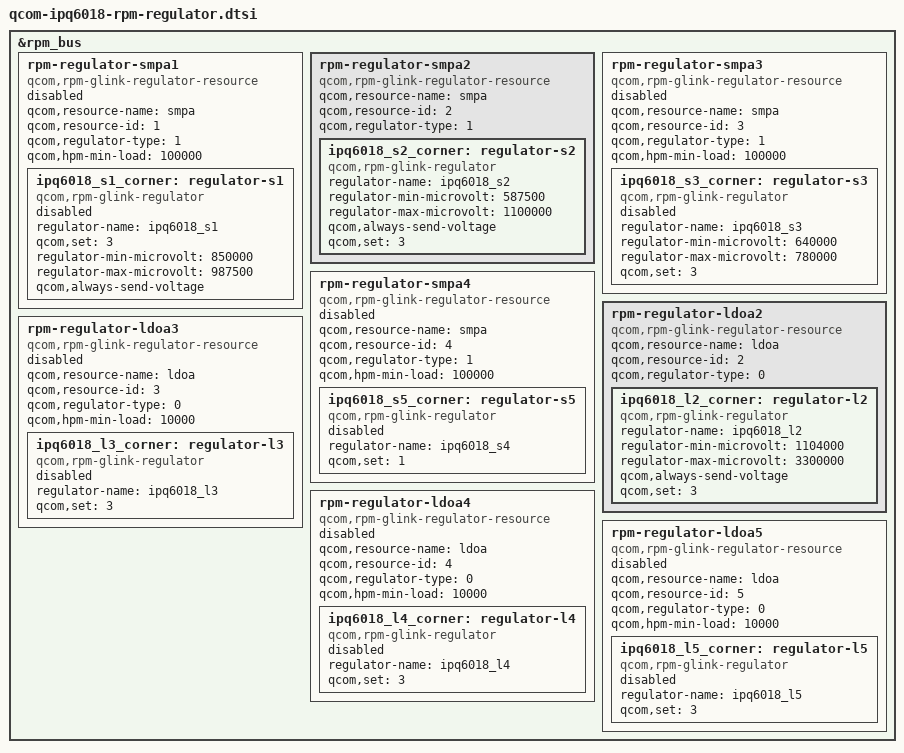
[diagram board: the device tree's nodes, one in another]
/*
 * Copyright (c) 2019, The Linux Foundation. All rights reserved.
 *
 * Permission to use, copy, modify, and/or distribute this software for any
 * purpose with or without fee is hereby granted, provided that the above
 * copyright notice and this permission notice appear in all copies.
 *
 * THE SOFTWARE IS PROVIDED "AS IS" AND THE AUTHOR DISCLAIMS ALL WARRANTIES
 * WITH REGARD TO THIS SOFTWARE INCLUDING ALL IMPLIED WARRANTIES OF
 * MERCHANTABILITY AND FITNESS. IN NO EVENT SHALL THE AUTHOR BE LIABLE FOR
 * ANY SPECIAL, DIRECT, INDIRECT, OR CONSEQUENTIAL DAMAGES OR ANY DAMAGES
 * WHATSOEVER RESULTING FROM LOSS OF USE, DATA OR PROFITS, WHETHER IN AN
 * ACTION OF CONTRACT, NEGLIGENCE OR OTHER TORTIOUS ACTION, ARISING OUT OF
 * OR IN CONNECTION WITH THE USE OR PERFORMANCE OF THIS SOFTWARE.
 */

&rpm_bus {
	rpm-regulator-smpa1 {
		compatible = "qcom,rpm-glink-regulator-resource";
		qcom,resource-name = "smpa";
		qcom,resource-id = <1>;
		qcom,regulator-type = <1>;
		qcom,hpm-min-load = <100000>;
		status = "disabled";

		ipq6018_s1_corner: regulator-s1 {
			compatible = "qcom,rpm-glink-regulator";
			regulator-name = "ipq6018_s1";
			qcom,set = <3>;
			regulator-min-microvolt = <850000>;
			regulator-max-microvolt = <987500>;
			qcom,always-send-voltage;
			status = "disabled";
		};
	};

	rpm-regulator-smpa2 {
		compatible = "qcom,rpm-glink-regulator-resource";
		qcom,resource-name = "smpa";
		qcom,resource-id = <2>;
		qcom,regulator-type = <1>;
		status = "ok";

		ipq6018_s2_corner: regulator-s2 {
			compatible = "qcom,rpm-glink-regulator";
			regulator-name = "ipq6018_s2";
			regulator-min-microvolt = <587500>;
			regulator-max-microvolt = <1100000>;
			qcom,always-send-voltage;
			qcom,set = <3>;
			status = "ok";
		};
	};

	rpm-regulator-smpa3 {
		compatible = "qcom,rpm-glink-regulator-resource";
		qcom,resource-name = "smpa";
		qcom,resource-id = <3>;
		qcom,regulator-type = <1>;
		qcom,hpm-min-load = <100000>;
		status = "disabled";

		ipq6018_s3_corner: regulator-s3 {
			compatible = "qcom,rpm-glink-regulator";
			regulator-name = "ipq6018_s3";
			regulator-min-microvolt = <640000>;
			regulator-max-microvolt = <780000>;
			qcom,set = <3>;
			status = "disabled";
		};
	};

	rpm-regulator-smpa4 {
		compatible = "qcom,rpm-glink-regulator-resource";
		qcom,resource-name = "smpa";
		qcom,resource-id = <4>;
		qcom,regulator-type = <1>;
		qcom,hpm-min-load = <100000>;
		status = "disabled";

		ipq6018_s5_corner: regulator-s5 {
			compatible = "qcom,rpm-glink-regulator";
			regulator-name = "ipq6018_s4";
			qcom,set = <1>;
			status = "disabled";
		};
	};

	rpm-regulator-ldoa2 {
		compatible = "qcom,rpm-glink-regulator-resource";
		qcom,resource-name = "ldoa";
		qcom,resource-id = <2>;
		qcom,regulator-type = <0>;
		status = "ok";

		ipq6018_l2_corner: regulator-l2 {
			compatible = "qcom,rpm-glink-regulator";
			regulator-name = "ipq6018_l2";
			regulator-min-microvolt = <1104000>;
			regulator-max-microvolt = <3300000>;
			qcom,always-send-voltage;
			qcom,set = <3>;
			status = "ok";
		};
	};

	rpm-regulator-ldoa3 {
		compatible = "qcom,rpm-glink-regulator-resource";
		qcom,resource-name = "ldoa";
		qcom,resource-id = <3>;
		qcom,regulator-type = <0>;
		qcom,hpm-min-load = <10000>;
		status = "disabled";

		ipq6018_l3_corner: regulator-l3 {
			compatible = "qcom,rpm-glink-regulator";
			regulator-name = "ipq6018_l3";
			qcom,set = <3>;
			status = "disabled";
		};
	};

	rpm-regulator-ldoa4 {
		compatible = "qcom,rpm-glink-regulator-resource";
		qcom,resource-name = "ldoa";
		qcom,resource-id = <4>;
		qcom,regulator-type = <0>;
		qcom,hpm-min-load = <10000>;
		status = "disabled";

		ipq6018_l4_corner: regulator-l4 {
			compatible = "qcom,rpm-glink-regulator";
			regulator-name = "ipq6018_l4";
			qcom,set = <3>;
			status = "disabled";
		};
	};

	rpm-regulator-ldoa5 {
		compatible = "qcom,rpm-glink-regulator-resource";
		qcom,resource-name = "ldoa";
		qcom,resource-id = <5>;
		qcom,regulator-type = <0>;
		qcom,hpm-min-load = <10000>;
		status = "disabled";

		ipq6018_l5_corner: regulator-l5 {
			compatible = "qcom,rpm-glink-regulator";
			regulator-name = "ipq6018_l5";
			qcom,set = <3>;
			status = "disabled";
		};
	};
};
